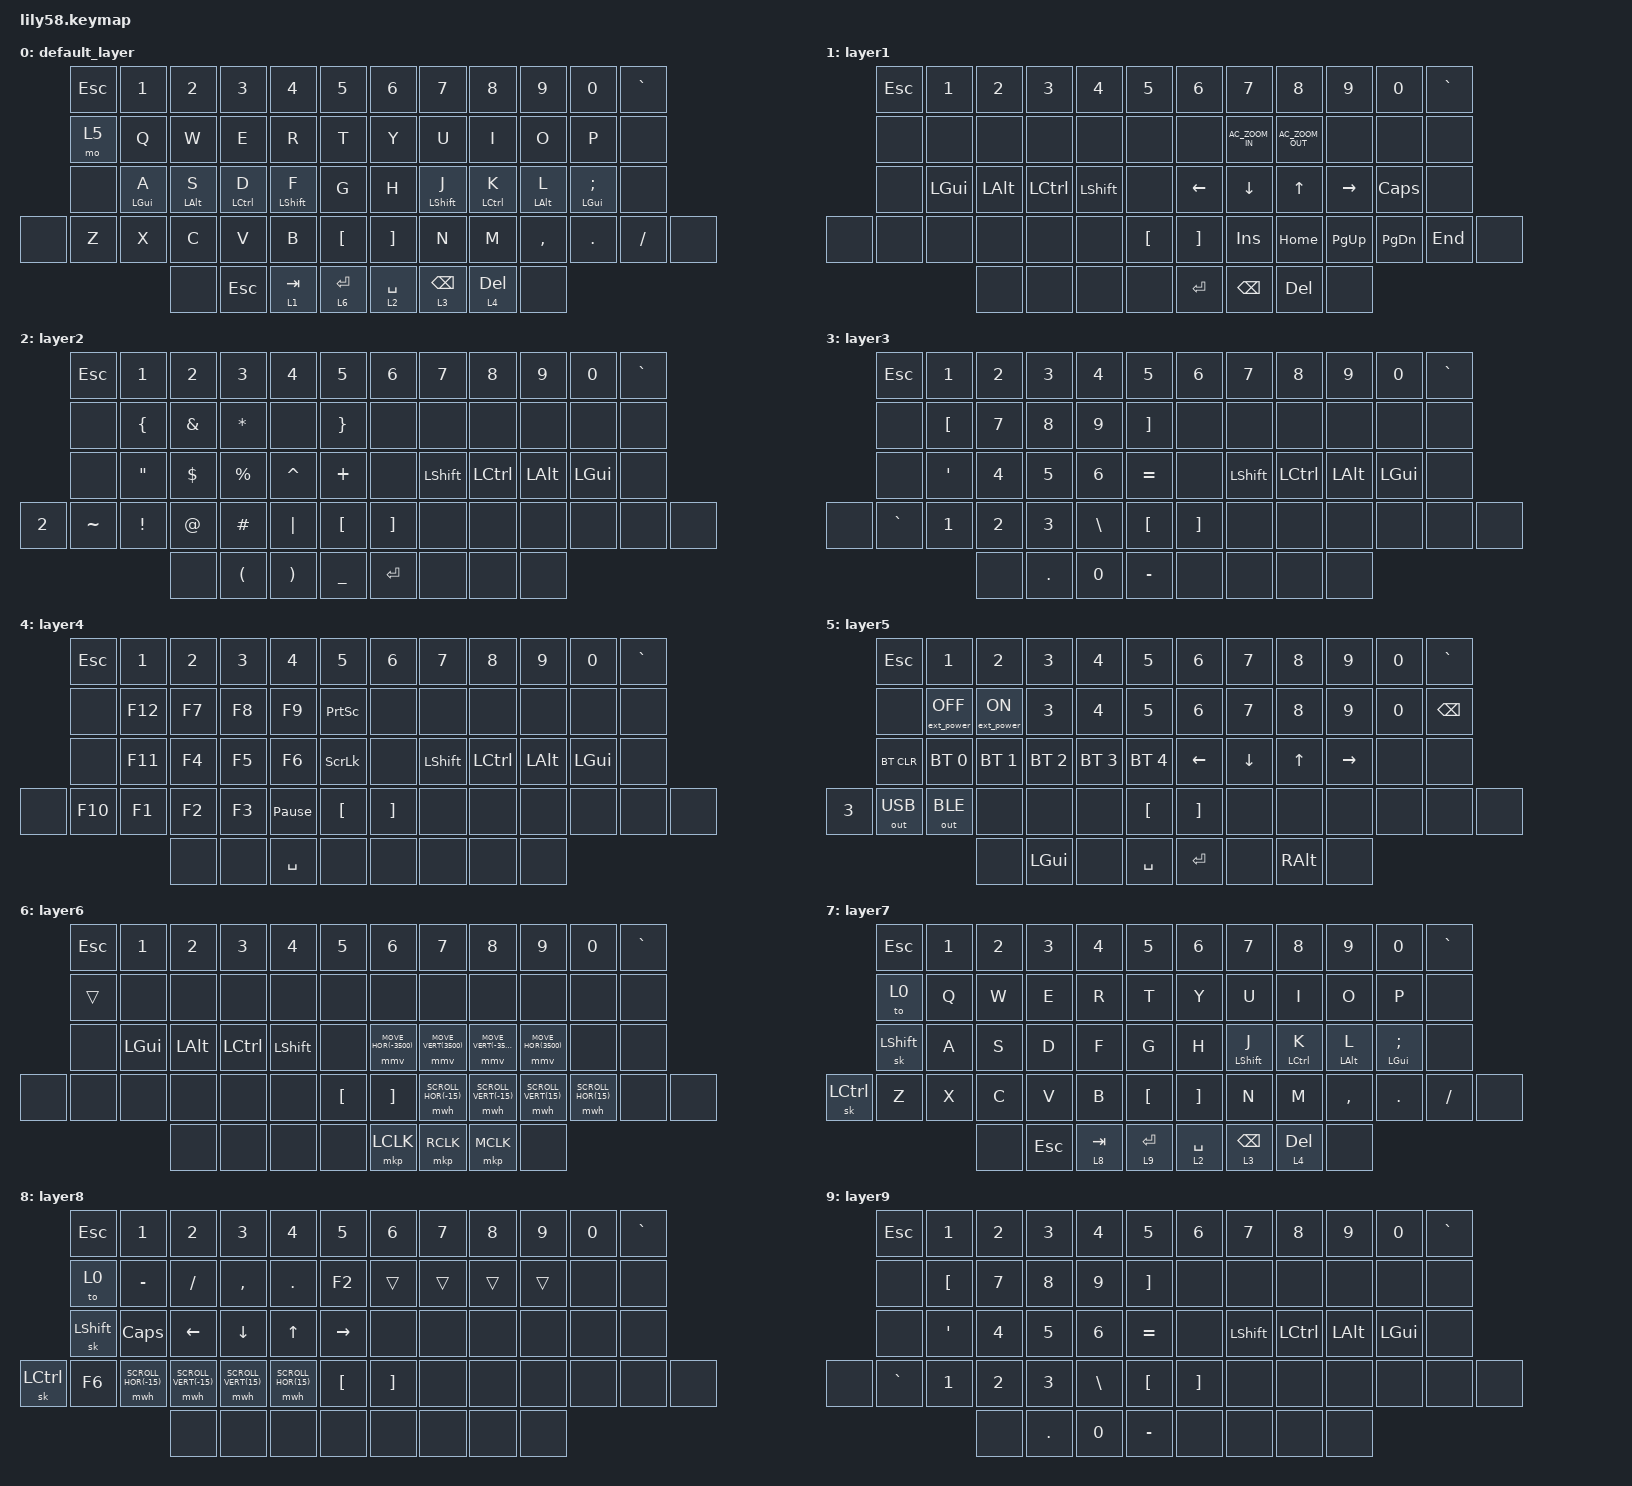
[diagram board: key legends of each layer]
/*
 * Copyright (c) 2020 The ZMK Contributors
 *
 * SPDX-License-Identifier: MIT
 */

#include <behaviors.dtsi>
#include <dt-bindings/zmk/bt.h>
#include <dt-bindings/zmk/ext_power.h>
#include <dt-bindings/zmk/keys.h>
#include <dt-bindings/zmk/mouse.h>
#include <dt-bindings/zmk/outputs.h>
// #include <dt-bindings/zmk/pointing.h> // 滑鼠功能 (mmv, msc, mkp)


&mmv {    
        time-to-max-speed-ms = <500>;
        acceleration-exponent=<1>;
};
&mwh {    
        time-to-max-speed-ms = <2000>;
        acceleration-exponent=<0>;
}; 
/ {
        combos{
                compatible = "zmk,combos";
                combo_spc {
                        timeout-ms = <50>;
                        key-positions = <13 16>;
                        bindings = <&kp SPACE>;
                        layers = <7>;
                };
                combo_p {
                        timeout-ms = <50>;
                        key-positions = <1 2>;
                        bindings = <&kp P>;
                        layers = <7>;
                };
                combo_o {
                        timeout-ms = <50>;
                        key-positions = <2 3>;
                        bindings = <&kp O>;
                        layers = <7>;
                };
                combo_h {
                        timeout-ms = <50>;
                        key-positions = <2 4>;
                        bindings = <&kp H>;
                        layers = <7>;
                };
                combo_k {
                        timeout-ms = <50>;
                        key-positions = <3 4>;
                        bindings = <&kp K>;
                        layers = <7>;
                };
                combo_y {
                        timeout-ms = <50>;
                        key-positions = <1 4>;
                        bindings = <&kp Y>;
                        layers = <7>;
                };
                combo_u {
                        timeout-ms = <50>;
                        key-positions = <13 15>;
                        bindings = <&kp U>;
                        layers = <7>;
                };
                combo_l {
                        timeout-ms = <50>;
                        key-positions = <25 26>;
                        bindings = <&kp L>;
                        layers = <7>;
                };
                combo_meta {
                        timeout-ms = <50>;
                        key-positions = <15 16>;
                        bindings = <&to LGUI>;
                        layers = <7>;
                };
                combo_alt {
                        timeout-ms = <50>;
                        key-positions = <14 16>;
                        bindings = <&to LALT>;
                        layers = <7>;
                };
                combo_bksp {
                        timeout-ms = <50>;
                        key-positions = <15 28>;
                        bindings = <&kp BSPC>;
                        layers = <7>;
                };
                combo_del {
                        timeout-ms = <50>;
                        key-positions = <16 27>;
                        bindings = <&kp DEL>;
                        layers = <7>;
                };
                combo_n {
                        timeout-ms = <50>;
                        key-positions = <26 27>;
                        bindings = <&kp N>;
                        layers = <7>;
                };
                combo_i {
                        timeout-ms = <50>;
                        key-positions = <27 28>;
                        bindings = <&kp I>;
                        layers = <7>;
                };
                combo_j {
                        timeout-ms = <50>;
                        key-positions = <26 28>;
                        bindings = <&kp J>;
                        layers = <7>;
                };
                combo_m {
                        timeout-ms = <50>;
                        key-positions = <25 28>;
                        bindings = <&kp M>;
                        layers = <7>;
                };
        };
};
/ {
        behaviors {
                mtt: mod_tap_tap {
                        compatible = "zmk,behavior-hold-tap";
                        label = "MOD_TAP_TAP";
                        #binding-cells = <2>;
                        flavor = "tap-preferred"; //was hold-preferred
                        tapping-term-ms = <150>;
                        quick-tap-ms = <200>;
                        bindings = <&kp>, <&kp>;
                };
                ltt: layer_tap_tap {
                        compatible = "zmk,behavior-hold-tap";
                        label = "LAYER_TAP_TAP";
                        #binding-cells = <2>;
                        flavor = "hold-preferred"; 
                        tapping-term-ms = <400>;
                        quick-tap-ms = <200>;
                        bindings = <&mo>, <&kp>;
                };                
        };

keymap {
                compatible = "zmk,keymap";

                default_layer {
                        bindings = <
   &kp ESC   &kp N1 &kp N2 &kp N3   &kp N4   &kp N5                     &kp N6 &kp N7   &kp N8    &kp N9  &kp N0   &kp GRAVE
   &mo 5  &kp Q      &kp W      &kp E       &kp R        &kp T   &kp Y &kp U        &kp I     &kp O   &kp P    &none
   &none  &mtt LGUI A &mtt LALT S &mtt LCTRL D &mtt LSHIFT F &kp G   &kp H &mtt LSHIFT J &mtt LCTRL K     &mtt LALT L &mtt LGUI SEMI &none
   &none  &kp Z      &kp X      &kp C       &kp V        &kp B &kp LBKT   &kp RBKT  &kp N &kp M        &kp COMMA       &kp DOT &kp FSLH &none
                  &none &kp ESC &ltt 1 TAB &ltt 6 RET   &ltt 2 SPACE &ltt 3 BSPC &ltt 4 DEL &none
                        >;
                };
                layer1 {
                        bindings = <
   &kp ESC   &kp N1 &kp N2 &kp N3   &kp N4   &kp N5                     &kp N6 &kp N7   &kp N8    &kp N9  &kp N0   &kp GRAVE
   &none &none    &none    &none     &none         &none      &none          &kp C_AC_ZOOM_IN &kp C_AC_ZOOM_OUT &none          &none        &none        
   &none &kp LGUI &kp LALT &kp LCTRL &kp LSHIFT    &none      &kp LEFT_ARROW &kp DOWN_ARROW   &kp UP_ARROW      &kp RIGHT_ARROW &kp CAPS      &none      
   &none &none    &none    &none     &none         &none   &kp LBKT   &kp RBKT    &kp INS        &kp HOME         &kp PG_UP         &kp PG_DN       &kp END        &none      
                  &none &none  &none     &none         &kp RET &kp BKSP   &kp DEL &none
                        >;
                };
                layer2 {
                        bindings = <
   &kp ESC   &kp N1 &kp N2 &kp N3   &kp N4   &kp N5                     &kp N6 &kp N7   &kp N8    &kp N9  &kp N0   &kp GRAVE
   &none &kp LBRC  &kp AMPS &kp ASTRK &none    &kp RBRC   &none  &none     &none    &none   &none  &none
   &none &kp DQT   &kp DLLR &kp PRCNT &kp CARET &kp PLUS   &none  &kp LSHIFT &kp LCTRL &kp LALT &kp LGUI &none        
   &kp N2 &kp TILDE &kp EXCL &kp AT    &kp HASH  &kp PIPE  &kp LBKT   &kp RBKT  &none  &none     &none    &none   &none   &none
                    	     &none &kp LPAR &kp RPAR   &kp UNDER   &kp RET   &none    &none &none
                        >;
                };
                layer3 { //numbers
                        bindings = <
   &kp ESC   &kp N1 &kp N2 &kp N3   &kp N4   &kp N5                     &kp N6 &kp N7   &kp N8    &kp N9  &kp N0   &kp GRAVE
   &none &kp LBKT  &kp N7 &kp N8 &kp N9 &kp RBKT    &none     &none     &none    &none   &none  &none
   &none &kp SQT   &kp N4 &kp N5 &kp N6 &kp EQUAL   &none  &kp LSHIFT &kp LCTRL &kp LALT &kp LGUI &none        
   &none &kp GRAVE &kp N1 &kp N2 &kp N3 &kp BSLH  &kp LBKT   &kp RBKT  &none  &none     &none    &none   &none   &none
                    	     &none &kp DOT &kp N0  &kp MINUS  &none     &none    &none &none
                        >;
                };
                layer4 { //f keys
                        bindings = <
   &kp ESC   &kp N1 &kp N2 &kp N3   &kp N4   &kp N5                     &kp N6 &kp N7   &kp N8    &kp N9  &kp N0   &kp GRAVE
   &none &kp F12 &kp F7 &kp F8 &kp F9 &kp PSCRN       &none     &none     &none    &none   &none  &none
   &none &kp F11 &kp F4 &kp F5 &kp F6 &kp SLCK        &none  &kp LSHIFT &kp LCTRL &kp LALT &kp LGUI &none        
   &none &kp F10 &kp F1 &kp F2 &kp F3 &kp PAUSE_BREAK  &kp LBKT   &kp RBKT  &none  &none     &none    &none   &none   &none
                    	     &none &none &kp SPACE  &none  &none     &none    &none &none
                        >;
                };
                layer5 {
                        bindings = <
   &kp ESC   &kp N1 &kp N2 &kp N3   &kp N4   &kp N5                     &kp N6 &kp N7   &kp N8    &kp N9  &kp N0   &kp GRAVE
   &none     &ext_power EP_OFF &ext_power EP_ON          &kp N3       &kp N4       &kp N5         &kp N6   &kp N7   &kp N8 &kp N9    &kp N0 &kp BSPC
   &bt BT_CLR &bt BT_SEL 0     &bt BT_SEL 1 &bt BT_SEL 2 &bt BT_SEL 3 &bt BT_SEL 4   &kp LEFT &kp DOWN &kp UP &kp RIGHT &none &none
   &kp N3     &out OUT_USB     &out OUT_BLE &none       &none       &none    &kp LBKT   &kp RBKT      &none   &none   &none &none    &none &none
                          	        &none &kp LGUI     &none       &kp SPACE      &kp RET  &none   &kp RALT &none
                        >;
                };
                layer6 { //mouse build from git@github.com:krikun98/zmk.git branch mouse-pr
                       bindings = <
   &kp ESC   &kp N1 &kp N2 &kp N3   &kp N4   &kp N5                     &kp N6 &kp N7   &kp N8    &kp N9  &kp N0   &kp GRAVE
   &trans &none    &none    &none     &none         &none      &none                 &none            &none          &none             &none &none        
   &none &kp LGUI &kp LALT &kp LCTRL &kp LSHIFT    &none      &mmv MOVE_HOR(-3500)   &mmv MOVE_VERT(3500)   &mmv MOVE_VERT(-3500)   &mmv MOVE_HOR(3500)   &none &none
   &none &none    &none    &none     &none         &none    &kp LBKT   &kp RBKT   &mwh SCROLL_HOR(-15) &mwh SCROLL_VERT(-15) &mwh SCROLL_VERT(15) &mwh SCROLL_HOR(15) &none &none      
                  &none &none    &none     &none         &mkp LCLK &mkp RCLK   &mkp MCLK &none
                       >;
                };
                layer7{
                        bindings = <
   &kp ESC   &kp N1 &kp N2 &kp N3   &kp N4   &kp N5                     &kp N6 &kp N7   &kp N8    &kp N9  &kp N0   &kp GRAVE
   &to 0      &kp Q      &kp W      &kp E       &kp R        &kp T        &kp Y &kp U        &kp I     &kp O   &kp P    &none
   &sk LSHIFT &kp A      &kp S      &kp D       &kp F        &kp G        &kp H &mtt LSHIFT J &mtt LCTRL K     &mtt LALT L &mtt LGUI SEMI &none
   &sk LCTRL  &kp Z      &kp X      &kp C       &kp V        &kp B   &kp LBKT   &kp RBKT      &kp N &kp M        &kp COMMA       &kp DOT &kp FSLH &none
                  &none &kp ESC &ltt 8 TAB &ltt 9 RET   &ltt 2 SPACE &ltt 3 BSPC &ltt 4 DEL &none
                        >;
                };
                layer8 { //arrows and scroll for left
                        bindings = <
   &kp ESC   &kp N1 &kp N2 &kp N3   &kp N4   &kp N5                     &kp N6 &kp N7   &kp N8    &kp N9  &kp N0   &kp GRAVE
   &to 0      &kp MINUS &kp FSLH             &kp COMMA             &kp DOT              &kp F2              &trans &trans &trans &trans  &none   &none      
   &sk LSHIFT &kp CAPS  &kp LEFT_ARROW       &kp DOWN_ARROW        &kp UP_ARROW         &kp RIGHT_ARROW     &none  &none  &none  &none   &none   &none        
   &sk LCTRL  &kp F6    &mwh SCROLL_HOR(-15) &mwh SCROLL_VERT(-15) &mwh SCROLL_VERT(15) &mwh SCROLL_HOR(15) &kp LBKT   &kp RBKT  &none  &none  &none  &none   &none   &none      
                  &none &none    &none     &none         &none      &none   &none &none
                        >;
                };
                layer9 { //numbers
                        bindings = <

   &kp ESC   &kp N1 &kp N2 &kp N3   &kp N4   &kp N5                     &kp N6 &kp N7   &kp N8    &kp N9  &kp N0   &kp GRAVE
   &none &kp LBKT  &kp N7 &kp N8 &kp N9 &kp RBKT    &none     &none     &none    &none   &none  &none
   &none &kp SQT   &kp N4 &kp N5 &kp N6 &kp EQUAL   &none  &kp LSHIFT &kp LCTRL &kp LALT &kp LGUI &none        
   &none &kp GRAVE &kp N1 &kp N2 &kp N3 &kp BSLH  &kp LBKT   &kp RBKT  &none  &none     &none    &none   &none   &none
                    	     &none &kp DOT &kp N0  &kp MINUS  &none     &none    &none &none
                        >;
                };
        };
//keymap {
//compatible = "zmk,keymap";
//
//default_layer {
//// ------------------------------------------------------------------------------------------------------------
//// |  ESC  |  1  |  2  |  3   |  4   |  5   |                   |  6   |  7    |  8    |  9   |   0   |   `   |
//// |  TAB  |  Q  |  W  |  E   |  R   |  T   |                   |  Y   |  U    |  I    |  O   |   P   |   -   |
//// |  CTRL |  A  |  S  |  D   |  F   |  G   |                   |  H   |  J    |  K    |  L   |   ;   |   '   |
//// | SHIFT |  Z  |  X  |  C   |  V   |  B   |   "["  |  |  "]"  |  N   |  M    |  ,    |  .   |   /   | SHIFT |
////                     | ALT  | GUI  | LOWER|  SPACE |  | ENTER | RAISE| BSPC  | GUI   |
//bindings = <
//&kp ESC   &kp N1 &kp N2 &kp N3   &kp N4   &kp N5                     &kp N6 &kp N7   &kp N8    &kp N9  &kp N0   &kp GRAVE
//&kp TAB   &kp Q  &kp W  &kp E    &kp R    &kp T                      &kp Y  &kp U    &kp I     &kp O   &kp P    &kp MINUS
//&kp LCTRL &kp A  &kp S  &kp D    &kp F    &kp G                      &kp H  &kp J    &kp K     &kp L   &kp SEMI &kp SQT
//&kp LSHFT &kp Z  &kp X  &kp C    &kp V    &kp B  &kp LBKT   &kp RBKT &kp N  &kp M    &kp COMMA &kp DOT &kp FSLH &kp RSHFT
//                        &kp LALT &kp LGUI &mo 1  &kp SPACE  &kp RET  &mo 2  &kp BSPC &kp RGUI
//>;
//
//sensor-bindings = <&inc_dec_kp C_VOL_UP C_VOL_DN>;
//};
//
//lower_layer {
//// ------------------------------------------------------------------------------------------------------------
//// | BTCLR | BT1 | BT2 |  BT3 |  BT4 |  BT5 |                   |      |       |       |      |       |       |
//// |  F1   |  F2 |  F3 |  F4  |  F5  |  F6  |                   |  F7  |  F8   |  F9   |  F10 |  F11  |  F12  |
//// |   `   |  !  |  @  |  #   |  $   |  %   |                   |  ^   |  &    |  *    |  (   |   )   |   ~   |
//// |       |     |     |      |      |      |        |  |       |      |  _    |  +    |  {   |   }   |  "|"  |
////                     |      |      |      |        |  |       |      |       |       |
//bindings = <
//&bt BT_CLR &bt BT_SEL 0     &bt BT_SEL 1      &bt BT_SEL 2      &bt BT_SEL 3 &bt BT_SEL 4                 &trans    &trans    &trans          &trans    &trans    &trans
//&kp F1     &kp F2           &kp F3            &kp F4            &kp F5       &kp F6                       &kp F7    &kp F8    &kp F9          &kp F10   &kp F11   &kp F12
//&kp GRAVE  &kp EXCL         &kp AT            &kp HASH          &kp DOLLAR   &kp PRCNT                    &kp CARET &kp AMPS  &kp KP_MULTIPLY &kp LPAR  &kp RPAR  &kp TILDE
//&trans     &ext_power EP_ON &ext_power EP_OFF &ext_power EP_TOG &trans       &trans    &trans   &trans    &trans    &kp MINUS &kp KP_PLUS     &kp LBRC  &kp RBRC  &kp PIPE
//                                              &trans            &trans       &trans    &trans   &trans    &trans    &trans    &trans
//>;
//
//sensor-bindings = <&inc_dec_kp C_VOL_UP C_VOL_DN>;
//};
//
//raise_layer {
//// ------------------------------------------------------------------------------------------------------------
//// |       |     |     |      |      |      |                   |      |       |       |      |       |       |
//// |   `   |  1  |  2  |  3   |  4   |  5   |                   |  6   |   7   |   8   |  9   |   0   |       |
//// |   F1  |  F2 |  F3 |  F4  |  F5  |  F6  |                   |      |   <-  |   v   |  ^   |  ->   |       |
//// |   F7  |  F8 |  F9 |  F10 |  F11 |  F12 |        |  |       |  +   |   -   |   =   |  [   |   ]   |   \   |
////                     |      |      |      |        |  |       |      |       |       |
//bindings = <
//&trans    &trans &trans &trans  &trans  &trans                       &trans      &trans    &trans    &trans   &trans    &trans
//&kp GRAVE &kp N1 &kp N2 &kp N3  &kp N4  &kp N5                       &kp N6      &kp N7    &kp N8    &kp N9   &kp N0    &trans
//&kp F1    &kp F2 &kp F3 &kp F4  &kp F5  &kp F6                       &trans      &kp LEFT  &kp DOWN  &kp UP   &kp RIGHT &trans
//&kp F7    &kp F8 &kp F9 &kp F10 &kp F11 &kp F12   &trans   &trans    &kp KP_PLUS &kp MINUS &kp EQUAL &kp LBKT &kp RBKT  &kp BSLH
//                        &trans  &trans  &trans    &trans   &trans    &trans      &trans    &trans
//>;
//
//sensor-bindings = <&inc_dec_kp C_VOL_UP C_VOL_DN>;
//};
//};
};
